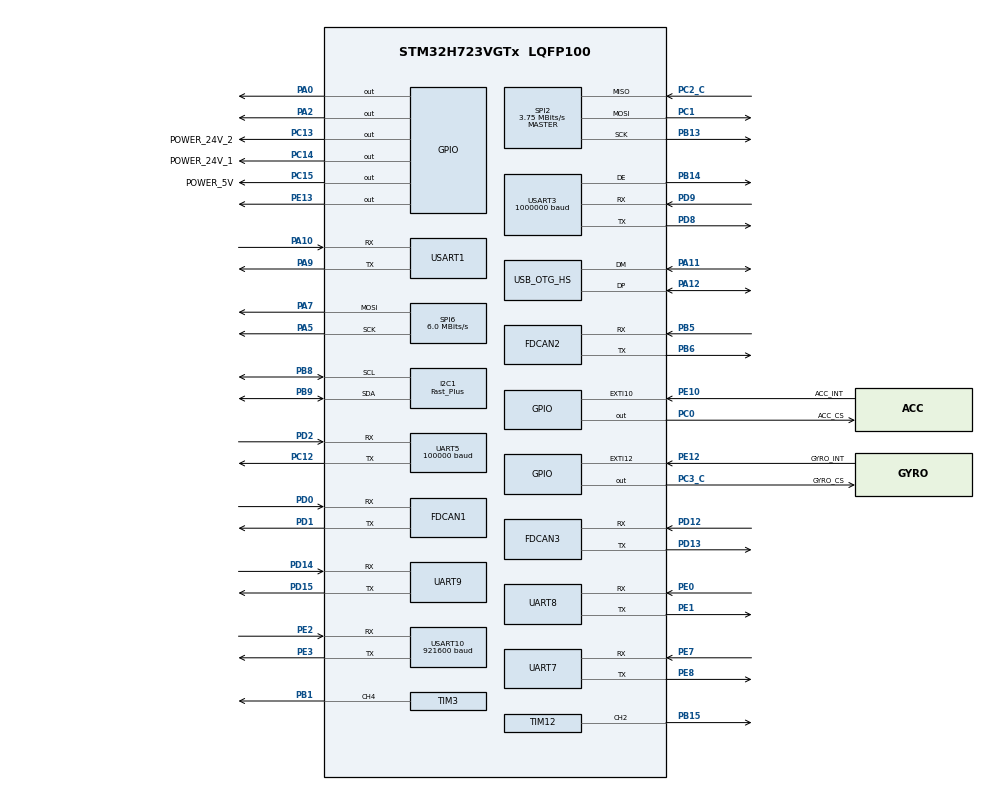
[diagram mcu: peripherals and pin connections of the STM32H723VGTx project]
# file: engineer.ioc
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ADC3.Channel-1\#ChannelRegularConversion=ADC_CHANNEL_TEMPSENSOR
ADC3.NbrOfConversionFlag=1
ADC3.OffsetNumber-1\#ChannelRegularConversion=ADC_OFFSET_NONE
ADC3.OffsetSign-1\#ChannelRegularConversion=ADC3_OFFSET_SIGN_NEGATIVE
ADC3.Rank-1\#ChannelRegularConversion=1
ADC3.SamplingTime-1\#ChannelRegularConversion=ADC3_SAMPLETIME_2CYCLES_5
Bdma.Request0=SPI6_TX
Bdma.RequestsNb=1
Bdma.SPI6_TX.0.Direction=DMA_MEMORY_TO_PERIPH
Bdma.SPI6_TX.0.EventEnable=DISABLE
Bdma.SPI6_TX.0.Instance=BDMA_Channel0
Bdma.SPI6_TX.0.MemDataAlignment=DMA_MDATAALIGN_BYTE
Bdma.SPI6_TX.0.MemInc=DMA_MINC_ENABLE
Bdma.SPI6_TX.0.Mode=DMA_NORMAL
Bdma.SPI6_TX.0.PeriphDataAlignment=DMA_PDATAALIGN_BYTE
Bdma.SPI6_TX.0.PeriphInc=DMA_PINC_DISABLE
Bdma.SPI6_TX.0.Polarity=HAL_DMAMUX_REQ_GEN_RISING
Bdma.SPI6_TX.0.Priority=DMA_PRIORITY_LOW
Bdma.SPI6_TX.0.RequestNumber=1
Bdma.SPI6_TX.0.SignalID=NONE
Bdma.SPI6_TX.0.SyncEnable=DISABLE
Bdma.SPI6_TX.0.SyncPolarity=HAL_DMAMUX_SYNC_NO_EVENT
Bdma.SPI6_TX.0.SyncRequestNumber=1
Bdma.SPI6_TX.0.SyncSignalID=NONE
CORTEX_M7.CPU_DCache=Disabled
CORTEX_M7.CPU_ICache=Disabled
CORTEX_M7.default_mode_Activation=0
Dma.Request0=UART5_RX
Dma.Request1=SPI2_RX
Dma.Request10=UART7_TX
Dma.Request11=UART9_RX
Dma.Request12=UART9_TX
Dma.Request13=UART8_RX
Dma.Request14=UART8_TX
Dma.Request2=SPI2_TX
Dma.Request3=USART10_RX
Dma.Request4=USART1_RX
Dma.Request5=USART1_TX
Dma.Request6=USART10_TX
Dma.Request7=USART3_RX
Dma.Request8=USART3_TX
Dma.Request9=UART7_RX
Dma.SPI2_RX.1.Direction=DMA_PERIPH_TO_MEMORY
Dma.SPI2_RX.1.EventEnable=DISABLE
Dma.SPI2_RX.1.FIFOMode=DMA_FIFOMODE_DISABLE
Dma.SPI2_RX.1.Instance=DMA1_Stream0
Dma.SPI2_RX.1.MemDataAlignment=DMA_MDATAALIGN_BYTE
Dma.SPI2_RX.1.MemInc=DMA_MINC_ENABLE
Dma.SPI2_RX.1.Mode=DMA_NORMAL
Dma.SPI2_RX.1.PeriphDataAlignment=DMA_PDATAALIGN_BYTE
Dma.SPI2_RX.1.PeriphInc=DMA_PINC_DISABLE
Dma.SPI2_RX.1.Polarity=HAL_DMAMUX_REQ_GEN_RISING
Dma.SPI2_RX.1.Priority=DMA_PRIORITY_VERY_HIGH
Dma.SPI2_RX.1.RequestNumber=1
Dma.SPI2_RX.1.SignalID=NONE
Dma.SPI2_RX.1.SyncEnable=DISABLE
Dma.SPI2_RX.1.SyncPolarity=HAL_DMAMUX_SYNC_NO_EVENT
Dma.SPI2_RX.1.SyncRequestNumber=1
Dma.SPI2_RX.1.SyncSignalID=NONE
Dma.SPI2_TX.2.Direction=DMA_MEMORY_TO_PERIPH
Dma.SPI2_TX.2.EventEnable=DISABLE
Dma.SPI2_TX.2.FIFOMode=DMA_FIFOMODE_DISABLE
Dma.SPI2_TX.2.Instance=DMA1_Stream1
Dma.SPI2_TX.2.MemDataAlignment=DMA_MDATAALIGN_BYTE
Dma.SPI2_TX.2.MemInc=DMA_MINC_ENABLE
Dma.SPI2_TX.2.Mode=DMA_NORMAL
Dma.SPI2_TX.2.PeriphDataAlignment=DMA_PDATAALIGN_BYTE
Dma.SPI2_TX.2.PeriphInc=DMA_PINC_DISABLE
Dma.SPI2_TX.2.Polarity=HAL_DMAMUX_REQ_GEN_RISING
Dma.SPI2_TX.2.Priority=DMA_PRIORITY_HIGH
Dma.SPI2_TX.2.RequestNumber=1
Dma.SPI2_TX.2.SignalID=NONE
Dma.SPI2_TX.2.SyncEnable=DISABLE
Dma.SPI2_TX.2.SyncPolarity=HAL_DMAMUX_SYNC_NO_EVENT
Dma.SPI2_TX.2.SyncRequestNumber=1
Dma.SPI2_TX.2.SyncSignalID=NONE
Dma.UART5_RX.0.Direction=DMA_PERIPH_TO_MEMORY
Dma.UART5_RX.0.EventEnable=DISABLE
Dma.UART5_RX.0.FIFOMode=DMA_FIFOMODE_DISABLE
Dma.UART5_RX.0.Instance=DMA1_Stream3
Dma.UART5_RX.0.MemDataAlignment=DMA_MDATAALIGN_BYTE
Dma.UART5_RX.0.MemInc=DMA_MINC_ENABLE
Dma.UART5_RX.0.Mode=DMA_NORMAL
Dma.UART5_RX.0.PeriphDataAlignment=DMA_PDATAALIGN_BYTE
Dma.UART5_RX.0.PeriphInc=DMA_PINC_DISABLE
Dma.UART5_RX.0.Polarity=HAL_DMAMUX_REQ_GEN_RISING
Dma.UART5_RX.0.Priority=DMA_PRIORITY_LOW
Dma.UART5_RX.0.RequestNumber=1
Dma.UART5_RX.0.SignalID=NONE
Dma.UART5_RX.0.SyncEnable=DISABLE
Dma.UART5_RX.0.SyncPolarity=HAL_DMAMUX_SYNC_NO_EVENT
Dma.UART5_RX.0.SyncRequestNumber=1
Dma.UART5_RX.0.SyncSignalID=NONE
Dma.UART7_RX.9.Direction=DMA_PERIPH_TO_MEMORY
Dma.UART7_RX.9.EventEnable=DISABLE
Dma.UART7_RX.9.FIFOMode=DMA_FIFOMODE_DISABLE
Dma.UART7_RX.9.Instance=DMA2_Stream1
Dma.UART7_RX.9.MemDataAlignment=DMA_MDATAALIGN_BYTE
Dma.UART7_RX.9.MemInc=DMA_MINC_ENABLE
Dma.UART7_RX.9.Mode=DMA_NORMAL
Dma.UART7_RX.9.PeriphDataAlignment=DMA_PDATAALIGN_BYTE
Dma.UART7_RX.9.PeriphInc=DMA_PINC_DISABLE
Dma.UART7_RX.9.Polarity=HAL_DMAMUX_REQ_GEN_RISING
Dma.UART7_RX.9.Priority=DMA_PRIORITY_LOW
Dma.UART7_RX.9.RequestNumber=1
Dma.UART7_RX.9.SignalID=NONE
Dma.UART7_RX.9.SyncEnable=DISABLE
Dma.UART7_RX.9.SyncPolarity=HAL_DMAMUX_SYNC_NO_EVENT
Dma.UART7_RX.9.SyncRequestNumber=1
Dma.UART7_RX.9.SyncSignalID=NONE
Dma.UART7_TX.10.Direction=DMA_MEMORY_TO_PERIPH
Dma.UART7_TX.10.EventEnable=DISABLE
Dma.UART7_TX.10.FIFOMode=DMA_FIFOMODE_DISABLE
Dma.UART7_TX.10.Instance=DMA2_Stream2
Dma.UART7_TX.10.MemDataAlignment=DMA_MDATAALIGN_BYTE
Dma.UART7_TX.10.MemInc=DMA_MINC_ENABLE
Dma.UART7_TX.10.Mode=DMA_NORMAL
Dma.UART7_TX.10.PeriphDataAlignment=DMA_PDATAALIGN_BYTE
Dma.UART7_TX.10.PeriphInc=DMA_PINC_DISABLE
Dma.UART7_TX.10.Polarity=HAL_DMAMUX_REQ_GEN_RISING
Dma.UART7_TX.10.Priority=DMA_PRIORITY_LOW
Dma.UART7_TX.10.RequestNumber=1
Dma.UART7_TX.10.SignalID=NONE
Dma.UART7_TX.10.SyncEnable=DISABLE
Dma.UART7_TX.10.SyncPolarity=HAL_DMAMUX_SYNC_NO_EVENT
Dma.UART7_TX.10.SyncRequestNumber=1
Dma.UART7_TX.10.SyncSignalID=NONE
Dma.UART8_RX.13.Direction=DMA_PERIPH_TO_MEMORY
Dma.UART8_RX.13.EventEnable=DISABLE
Dma.UART8_RX.13.FIFOMode=DMA_FIFOMODE_DISABLE
Dma.UART8_RX.13.Instance=DMA2_Stream5
Dma.UART8_RX.13.MemDataAlignment=DMA_MDATAALIGN_BYTE
Dma.UART8_RX.13.MemInc=DMA_MINC_ENABLE
Dma.UART8_RX.13.Mode=DMA_NORMAL
Dma.UART8_RX.13.PeriphDataAlignment=DMA_PDATAALIGN_BYTE
Dma.UART8_RX.13.PeriphInc=DMA_PINC_DISABLE
Dma.UART8_RX.13.Polarity=HAL_DMAMUX_REQ_GEN_RISING
Dma.UART8_RX.13.Priority=DMA_PRIORITY_LOW
Dma.UART8_RX.13.RequestNumber=1
Dma.UART8_RX.13.SignalID=NONE
Dma.UART8_RX.13.SyncEnable=DISABLE
Dma.UART8_RX.13.SyncPolarity=HAL_DMAMUX_SYNC_NO_EVENT
Dma.UART8_RX.13.SyncRequestNumber=1
Dma.UART8_RX.13.SyncSignalID=NONE
Dma.UART8_TX.14.Direction=DMA_MEMORY_TO_PERIPH
Dma.UART8_TX.14.EventEnable=DISABLE
Dma.UART8_TX.14.FIFOMode=DMA_FIFOMODE_DISABLE
Dma.UART8_TX.14.Instance=DMA2_Stream6
Dma.UART8_TX.14.MemDataAlignment=DMA_MDATAALIGN_BYTE
Dma.UART8_TX.14.MemInc=DMA_MINC_ENABLE
Dma.UART8_TX.14.Mode=DMA_NORMAL
Dma.UART8_TX.14.PeriphDataAlignment=DMA_PDATAALIGN_BYTE
Dma.UART8_TX.14.PeriphInc=DMA_PINC_DISABLE
Dma.UART8_TX.14.Polarity=HAL_DMAMUX_REQ_GEN_RISING
Dma.UART8_TX.14.Priority=DMA_PRIORITY_LOW
Dma.UART8_TX.14.RequestNumber=1
Dma.UART8_TX.14.SignalID=NONE
Dma.UART8_TX.14.SyncEnable=DISABLE
Dma.UART8_TX.14.SyncPolarity=HAL_DMAMUX_SYNC_NO_EVENT
Dma.UART8_TX.14.SyncRequestNumber=1
Dma.UART8_TX.14.SyncSignalID=NONE
Dma.UART9_RX.11.Direction=DMA_PERIPH_TO_MEMORY
Dma.UART9_RX.11.EventEnable=DISABLE
Dma.UART9_RX.11.FIFOMode=DMA_FIFOMODE_DISABLE
Dma.UART9_RX.11.Instance=DMA2_Stream3
Dma.UART9_RX.11.MemDataAlignment=DMA_MDATAALIGN_BYTE
Dma.UART9_RX.11.MemInc=DMA_MINC_ENABLE
Dma.UART9_RX.11.Mode=DMA_NORMAL
Dma.UART9_RX.11.PeriphDataAlignment=DMA_PDATAALIGN_BYTE
Dma.UART9_RX.11.PeriphInc=DMA_PINC_DISABLE
Dma.UART9_RX.11.Polarity=HAL_DMAMUX_REQ_GEN_RISING
Dma.UART9_RX.11.Priority=DMA_PRIORITY_LOW
Dma.UART9_RX.11.RequestNumber=1
Dma.UART9_RX.11.SignalID=NONE
Dma.UART9_RX.11.SyncEnable=DISABLE
Dma.UART9_RX.11.SyncPolarity=HAL_DMAMUX_SYNC_NO_EVENT
Dma.UART9_RX.11.SyncRequestNumber=1
Dma.UART9_RX.11.SyncSignalID=NONE
Dma.UART9_TX.12.Direction=DMA_MEMORY_TO_PERIPH
Dma.UART9_TX.12.EventEnable=DISABLE
Dma.UART9_TX.12.FIFOMode=DMA_FIFOMODE_DISABLE
Dma.UART9_TX.12.Instance=DMA2_Stream4
Dma.UART9_TX.12.MemDataAlignment=DMA_MDATAALIGN_BYTE
Dma.UART9_TX.12.MemInc=DMA_MINC_ENABLE
Dma.UART9_TX.12.Mode=DMA_NORMAL
Dma.UART9_TX.12.PeriphDataAlignment=DMA_PDATAALIGN_BYTE
Dma.UART9_TX.12.PeriphInc=DMA_PINC_DISABLE
Dma.UART9_TX.12.Polarity=HAL_DMAMUX_REQ_GEN_RISING
Dma.UART9_TX.12.Priority=DMA_PRIORITY_LOW
Dma.UART9_TX.12.RequestNumber=1
Dma.UART9_TX.12.SignalID=NONE
Dma.UART9_TX.12.SyncEnable=DISABLE
Dma.UART9_TX.12.SyncPolarity=HAL_DMAMUX_SYNC_NO_EVENT
Dma.UART9_TX.12.SyncRequestNumber=1
Dma.UART9_TX.12.SyncSignalID=NONE
Dma.USART10_RX.3.Direction=DMA_PERIPH_TO_MEMORY
Dma.USART10_RX.3.EventEnable=DISABLE
Dma.USART10_RX.3.FIFOMode=DMA_FIFOMODE_DISABLE
Dma.USART10_RX.3.Instance=DMA1_Stream2
Dma.USART10_RX.3.MemDataAlignment=DMA_MDATAALIGN_BYTE
Dma.USART10_RX.3.MemInc=DMA_MINC_ENABLE
Dma.USART10_RX.3.Mode=DMA_NORMAL
Dma.USART10_RX.3.PeriphDataAlignment=DMA_PDATAALIGN_BYTE
Dma.USART10_RX.3.PeriphInc=DMA_PINC_DISABLE
Dma.USART10_RX.3.Polarity=HAL_DMAMUX_REQ_GEN_RISING
Dma.USART10_RX.3.Priority=DMA_PRIORITY_MEDIUM
Dma.USART10_RX.3.RequestNumber=1
Dma.USART10_RX.3.SignalID=NONE
Dma.USART10_RX.3.SyncEnable=DISABLE
Dma.USART10_RX.3.SyncPolarity=HAL_DMAMUX_SYNC_NO_EVENT
Dma.USART10_RX.3.SyncRequestNumber=1
Dma.USART10_RX.3.SyncSignalID=NONE
Dma.USART10_TX.6.Direction=DMA_MEMORY_TO_PERIPH
Dma.USART10_TX.6.EventEnable=DISABLE
Dma.USART10_TX.6.FIFOMode=DMA_FIFOMODE_DISABLE
Dma.USART10_TX.6.Instance=DMA1_Stream6
Dma.USART10_TX.6.MemDataAlignment=DMA_MDATAALIGN_BYTE
Dma.USART10_TX.6.MemInc=DMA_MINC_ENABLE
Dma.USART10_TX.6.Mode=DMA_NORMAL
Dma.USART10_TX.6.PeriphDataAlignment=DMA_PDATAALIGN_BYTE
Dma.USART10_TX.6.PeriphInc=DMA_PINC_DISABLE
Dma.USART10_TX.6.Polarity=HAL_DMAMUX_REQ_GEN_RISING
Dma.USART10_TX.6.Priority=DMA_PRIORITY_LOW
Dma.USART10_TX.6.RequestNumber=1
Dma.USART10_TX.6.SignalID=NONE
Dma.USART10_TX.6.SyncEnable=DISABLE
Dma.USART10_TX.6.SyncPolarity=HAL_DMAMUX_SYNC_NO_EVENT
Dma.USART10_TX.6.SyncRequestNumber=1
Dma.USART10_TX.6.SyncSignalID=NONE
Dma.USART1_RX.4.Direction=DMA_PERIPH_TO_MEMORY
Dma.USART1_RX.4.EventEnable=DISABLE
Dma.USART1_RX.4.FIFOMode=DMA_FIFOMODE_DISABLE
Dma.USART1_RX.4.Instance=DMA1_Stream4
Dma.USART1_RX.4.MemDataAlignment=DMA_MDATAALIGN_BYTE
Dma.USART1_RX.4.MemInc=DMA_MINC_ENABLE
Dma.USART1_RX.4.Mode=DMA_NORMAL
Dma.USART1_RX.4.PeriphDataAlignment=DMA_PDATAALIGN_BYTE
Dma.USART1_RX.4.PeriphInc=DMA_PINC_DISABLE
Dma.USART1_RX.4.Polarity=HAL_DMAMUX_REQ_GEN_RISING
Dma.USART1_RX.4.Priority=DMA_PRIORITY_LOW
Dma.USART1_RX.4.RequestNumber=1
Dma.USART1_RX.4.SignalID=NONE
Dma.USART1_RX.4.SyncEnable=DISABLE
Dma.USART1_RX.4.SyncPolarity=HAL_DMAMUX_SYNC_NO_EVENT
Dma.USART1_RX.4.SyncRequestNumber=1
Dma.USART1_RX.4.SyncSignalID=NONE
Dma.USART1_TX.5.Direction=DMA_MEMORY_TO_PERIPH
Dma.USART1_TX.5.EventEnable=DISABLE
Dma.USART1_TX.5.FIFOMode=DMA_FIFOMODE_DISABLE
Dma.USART1_TX.5.Instance=DMA1_Stream5
Dma.USART1_TX.5.MemDataAlignment=DMA_MDATAALIGN_BYTE
Dma.USART1_TX.5.MemInc=DMA_MINC_ENABLE
Dma.USART1_TX.5.Mode=DMA_NORMAL
Dma.USART1_TX.5.PeriphDataAlignment=DMA_PDATAALIGN_BYTE
Dma.USART1_TX.5.PeriphInc=DMA_PINC_DISABLE
Dma.USART1_TX.5.Polarity=HAL_DMAMUX_REQ_GEN_RISING
Dma.USART1_TX.5.Priority=DMA_PRIORITY_LOW
Dma.USART1_TX.5.RequestNumber=1
Dma.USART1_TX.5.SignalID=NONE
Dma.USART1_TX.5.SyncEnable=DISABLE
Dma.USART1_TX.5.SyncPolarity=HAL_DMAMUX_SYNC_NO_EVENT
Dma.USART1_TX.5.SyncRequestNumber=1
Dma.USART1_TX.5.SyncSignalID=NONE
Dma.USART3_RX.7.Direction=DMA_PERIPH_TO_MEMORY
Dma.USART3_RX.7.EventEnable=DISABLE
Dma.USART3_RX.7.FIFOMode=DMA_FIFOMODE_DISABLE
Dma.USART3_RX.7.Instance=DMA1_Stream7
Dma.USART3_RX.7.MemDataAlignment=DMA_MDATAALIGN_BYTE
Dma.USART3_RX.7.MemInc=DMA_MINC_ENABLE
Dma.USART3_RX.7.Mode=DMA_NORMAL
Dma.USART3_RX.7.PeriphDataAlignment=DMA_PDATAALIGN_BYTE
Dma.USART3_RX.7.PeriphInc=DMA_PINC_DISABLE
Dma.USART3_RX.7.Polarity=HAL_DMAMUX_REQ_GEN_RISING
Dma.USART3_RX.7.Priority=DMA_PRIORITY_LOW
Dma.USART3_RX.7.RequestNumber=1
Dma.USART3_RX.7.SignalID=NONE
Dma.USART3_RX.7.SyncEnable=DISABLE
Dma.USART3_RX.7.SyncPolarity=HAL_DMAMUX_SYNC_NO_EVENT
Dma.USART3_RX.7.SyncRequestNumber=1
Dma.USART3_RX.7.SyncSignalID=NONE
Dma.USART3_TX.8.Direction=DMA_MEMORY_TO_PERIPH
Dma.USART3_TX.8.EventEnable=DISABLE
Dma.USART3_TX.8.FIFOMode=DMA_FIFOMODE_DISABLE
Dma.USART3_TX.8.Instance=DMA2_Stream0
Dma.USART3_TX.8.MemDataAlignment=DMA_MDATAALIGN_BYTE
Dma.USART3_TX.8.MemInc=DMA_MINC_ENABLE
Dma.USART3_TX.8.Mode=DMA_NORMAL
Dma.USART3_TX.8.PeriphDataAlignment=DMA_PDATAALIGN_BYTE
Dma.USART3_TX.8.PeriphInc=DMA_PINC_DISABLE
Dma.USART3_TX.8.Polarity=HAL_DMAMUX_REQ_GEN_RISING
Dma.USART3_TX.8.Priority=DMA_PRIORITY_LOW
Dma.USART3_TX.8.RequestNumber=1
Dma.USART3_TX.8.SignalID=NONE
Dma.USART3_TX.8.SyncEnable=DISABLE
Dma.USART3_TX.8.SyncPolarity=HAL_DMAMUX_SYNC_NO_EVENT
Dma.USART3_TX.8.SyncRequestNumber=1
Dma.USART3_TX.8.SyncSignalID=NONE
FDCAN1.AutoRetransmission=ENABLE
FDCAN1.CalculateBaudRateNominal=999999
FDCAN1.CalculateTimeBitNominal=1000
FDCAN1.CalculateTimeQuantumNominal=83.33333333333334
FDCAN1.DataSyncJumpWidth=2
FDCAN1.DataTimeSeg1=13
FDCAN1.DataTimeSeg2=2
FDCAN1.ExtFiltersNbr=4
FDCAN1.NominalPrescaler=10
FDCAN1.NominalSyncJumpWidth=20
FDCAN1.NominalTimeSeg1=7
FDCAN1.NominalTimeSeg2=4
FDCAN1.ProtocolException=ENABLE
FDCAN1.RxBuffersNbr=2
FDCAN1.RxFifo0ElmtsNbr=8
FDCAN1.RxFifo1ElmtsNbr=8
FDCAN1.StdFiltersNbr=4
FDCAN1.TxBuffersNbr=8
FDCAN1.TxEventsNbr=8
FDCAN1.TxFifoQueueElmtsNbr=8
FDCAN2.AutoRetransmission=ENABLE
FDCAN2.CalculateBaudRateNominal=999999
FDCAN2.CalculateTimeBitNominal=1000
FDCAN2.CalculateTimeQuantumNominal=83.33333333333334
FDCAN2.DataSyncJumpWidth=2
FDCAN2.DataTimeSeg1=13
FDCAN2.DataTimeSeg2=2
FDCAN2.ExtFiltersNbr=4
FDCAN2.MessageRAMOffset=0x406
FDCAN2.NominalPrescaler=10
FDCAN2.NominalSyncJumpWidth=20
FDCAN2.NominalTimeSeg1=7
FDCAN2.NominalTimeSeg2=4
FDCAN2.ProtocolException=ENABLE
FDCAN2.RxBuffersNbr=3
FDCAN2.RxFifo0ElmtsNbr=8
FDCAN2.RxFifo1ElmtsNbr=8
FDCAN2.StdFiltersNbr=4
FDCAN2.TxBuffersNbr=8
FDCAN2.TxEventsNbr=8
FDCAN2.TxFifoQueueElmtsNbr=8
FDCAN3.AutoRetransmission=ENABLE
FDCAN3.CalculateBaudRateNominal=999999
FDCAN3.CalculateTimeBitNominal=1000
FDCAN3.CalculateTimeQuantumNominal=83.33333333333334
FDCAN3.DataSyncJumpWidth=2
FDCAN3.DataTimeSeg1=13
FDCAN3.DataTimeSeg2=2
FDCAN3.ExtFiltersNbr=4
FDCAN3.MessageRAMOffset=0x812
FDCAN3.NominalPrescaler=10
FDCAN3.NominalSyncJumpWidth=20
FDCAN3.NominalTimeSeg1=7
FDCAN3.NominalTimeSeg2=4
FDCAN3.ProtocolException=ENABLE
FDCAN3.RxBuffersNbr=2
FDCAN3.RxFifo0ElmtsNbr=8
FDCAN3.RxFifo1ElmtsNbr=8
FDCAN3.StdFiltersNbr=4
FDCAN3.TxBuffersNbr=8
FDCAN3.TxEventsNbr=8
FDCAN3.TxFifoQueueElmtsNbr=8
FREERTOS.INCLUDE_uxTaskGetStackHighWaterMark=1
FREERTOS.INCLUDE_vTaskDelayUntil=1
FREERTOS.INCLUDE_xEventGroupSetBitFromISR=1
FREERTOS.INCLUDE_xTaskGetHandle=1
FREERTOS.INCLUDE_xTimerPendFunctionCall=1
FREERTOS.Mutexes01=CAN1Mutex,Dynamic,NULL,Depleted;CAN2Mutex,Dynamic,NULL,Available
FREERTOS.Tasks01=defaultTask,3,256,StartDefaultTask,As weak,NULL,Dynamic,NULL,NULL;LED_TASK,-1,256,OS_LedTask,As weak,NULL,Dynamic,NULL,NULL;IMU_TASK,2,512,OS_IMUTask,As weak,NULL,Dynamic,NULL,NULL;DEBUG_TASK,-1,256,OS_DebugTask,As weak,NULL,Dynamic,NULL,NULL;PC_Task,0,384,OS_PCTask,As weak,NULL,Dynamic,NULL,NULL;BUZZER_TASK,0,256,OS_BuzzerTask,As weak,NULL,Dynamic,NULL,NULL
FREERTOS.configENABLE_FPU=1
FREERTOS.configGENERATE_RUN_TIME_STATS=1
FREERTOS.configTOTAL_HEAP_SIZE=40000
FREERTOS.configUSE_RECURSIVE_MUTEXES=1
FREERTOS.configUSE_STATS_FORMATTING_FUNCTIONS=1
FREERTOS.configUSE_TIMERS=1
FREERTOS.configUSE_TRACE_FACILITY=1
I2C1.CustomTiming=Disabled
I2C1.I2C_Speed_Mode=I2C_Fast_Plus
I2C1.Speed=1000
I2C1.Timing=0x0050174F
IWDG1.Prescaler=IWDG_PRESCALER_4
IWDG1.Reload=1024
Mcu.Family=STM32H7
Mcu.Name=STM32H723VGTx
Mcu.Package=LQFP100
NVIC.BDMA_Channel0_IRQn=true\:5\:0\:false\:false\:true\:true\:false\:true\:true
NVIC.DMA1_Stream0_IRQn=true\:5\:0\:false\:false\:true\:false\:false\:true\:true
NVIC.DMA1_Stream1_IRQn=true\:5\:0\:false\:false\:true\:false\:false\:true\:true
NVIC.DMA1_Stream2_IRQn=true\:5\:0\:false\:false\:true\:true\:false\:true\:true
NVIC.DMA1_Stream3_IRQn=true\:5\:0\:false\:false\:true\:false\:false\:true\:true
NVIC.DMA1_Stream4_IRQn=true\:5\:0\:false\:false\:true\:true\:false\:true\:true
NVIC.DMA1_Stream5_IRQn=true\:5\:0\:false\:false\:true\:true\:false\:true\:true
NVIC.DMA1_Stream6_IRQn=true\:5\:0\:false\:false\:true\:true\:false\:true\:true
NVIC.DMA1_Stream7_IRQn=true\:5\:0\:false\:false\:true\:true\:false\:true\:true
NVIC.DMA2_Stream0_IRQn=true\:5\:0\:false\:false\:true\:true\:false\:true\:true
NVIC.DMA2_Stream1_IRQn=true\:5\:0\:false\:false\:true\:true\:false\:true\:true
NVIC.DMA2_Stream2_IRQn=true\:5\:0\:false\:false\:true\:true\:false\:true\:true
NVIC.DMA2_Stream3_IRQn=true\:5\:0\:false\:false\:true\:true\:false\:true\:true
NVIC.DMA2_Stream4_IRQn=true\:5\:0\:false\:false\:true\:true\:false\:true\:true
NVIC.DMA2_Stream5_IRQn=true\:5\:0\:false\:false\:true\:true\:false\:true\:true
NVIC.DMA2_Stream6_IRQn=true\:5\:0\:false\:false\:true\:true\:false\:true\:true
NVIC.EXTI15_10_IRQn=true\:5\:0\:false\:false\:true\:true\:true\:true\:true
NVIC.FDCAN1_IT0_IRQn=true\:5\:0\:false\:false\:true\:true\:true\:true\:true
NVIC.FDCAN1_IT1_IRQn=true\:5\:0\:false\:false\:true\:true\:true\:true\:true
NVIC.FDCAN2_IT0_IRQn=true\:5\:0\:false\:false\:true\:true\:true\:true\:true
NVIC.FDCAN2_IT1_IRQn=true\:5\:0\:false\:false\:true\:true\:true\:true\:true
NVIC.FDCAN3_IT0_IRQn=true\:5\:0\:false\:false\:true\:true\:true\:true\:true
NVIC.FDCAN3_IT1_IRQn=true\:5\:0\:false\:false\:true\:true\:true\:true\:true
NVIC.I2C1_ER_IRQn=true\:5\:0\:false\:false\:true\:true\:true\:true\:true
NVIC.I2C1_EV_IRQn=true\:5\:0\:false\:false\:true\:true\:true\:true\:true
NVIC.OTG_HS_IRQn=true\:5\:0\:false\:false\:true\:true\:false\:true\:true
NVIC.PriorityGroup=NVIC_PRIORITYGROUP_4
NVIC.SPI2_IRQn=true\:5\:0\:false\:false\:true\:true\:false\:true\:true
NVIC.SPI6_IRQn=true\:5\:0\:false\:false\:true\:true\:true\:true\:true
NVIC.TIM17_IRQn=true\:15\:0\:false\:false\:true\:false\:false\:true\:true
NVIC.TIM6_DAC_IRQn=true\:5\:0\:false\:false\:true\:true\:true\:true\:true
NVIC.TimeBase=TIM17_IRQn
NVIC.TimeBaseIP=TIM17
NVIC.UART5_IRQn=true\:5\:0\:false\:false\:true\:true\:true\:true\:true
NVIC.UART7_IRQn=true\:5\:0\:false\:false\:true\:true\:true\:true\:true
NVIC.UART8_IRQn=true\:5\:0\:false\:false\:true\:true\:true\:true\:true
NVIC.UART9_IRQn=true\:5\:0\:false\:false\:true\:true\:true\:true\:true
NVIC.USART10_IRQn=true\:5\:0\:false\:false\:true\:true\:true\:true\:true
NVIC.USART1_IRQn=true\:5\:0\:false\:false\:true\:true\:true\:true\:true
NVIC.USART3_IRQn=true\:5\:0\:false\:false\:true\:true\:true\:true\:true
PA0.GPIO_ModeDefaultOutputPP=GPIO_MODE_OUTPUT_OD
PA0.GPIO_PuPd=GPIO_NOPULL
PA0.GPIO_Speed=GPIO_SPEED_FREQ_VERY_HIGH
PA0.PinState=GPIO_PIN_SET
PA0.Signal=GPIO_Output
PA10.Mode=Asynchronous
PA10.Signal=USART1_RX
PA11.Mode=Device_Only_FS
PA11.Signal=USB_OTG_HS_DM
PA12.Mode=Device_Only_FS
PA12.Signal=USB_OTG_HS_DP
PA13(JTMS/SWDIO).Mode=Serial_Wire
PA13(JTMS/SWDIO).Signal=DEBUG_JTMS-SWDIO
PA14(JTCK/SWCLK).Mode=Serial_Wire
PA14(JTCK/SWCLK).Signal=DEBUG_JTCK-SWCLK
PA2.Signal=GPIO_Output
PA5.Mode=TX_Only_Simplex_Unidirect_Master
PA5.Signal=SPI6_SCK
PA7.Mode=TX_Only_Simplex_Unidirect_Master
PA7.Signal=SPI6_MOSI
PA9.Mode=Asynchronous
PA9.Signal=USART1_TX
PB1.Signal=S_TIM3_CH4
PB13.Mode=Full_Duplex_Master
PB13.Signal=SPI2_SCK
PB14.Mode=Hardware Flow Control (RS485)
PB14.Signal=USART3_DE
PB15.Signal=S_TIM12_CH2
PB5.Mode=FDCAN_Activate
PB5.Signal=FDCAN2_RX
PB6.Mode=FDCAN_Activate
PB6.Signal=FDCAN2_TX
PB8.GPIO_Pu=GPIO_NOPULL
PB8.GPIO_Speed=GPIO_SPEED_FREQ_VERY_HIGH
PB8.Mode=I2C
PB8.Signal=I2C1_SCL
PB9.GPIO_Pu=GPIO_NOPULL
PB9.GPIO_Speed=GPIO_SPEED_FREQ_VERY_HIGH
PB9.Mode=I2C
PB9.Signal=I2C1_SDA
PC0.GPIO_Label=ACC_CS
PC0.GPIO_Speed=GPIO_SPEED_FREQ_VERY_HIGH
PC0.PinState=GPIO_PIN_SET
PC0.Signal=GPIO_Output
PC1.Mode=Full_Duplex_Master
PC1.Signal=SPI2_MOSI
PC12.Mode=Asynchronous
PC12.Signal=UART5_TX
PC13.GPIO_Label=POWER_24V_2
PC13.Signal=GPIO_Output
PC14-OSC32_IN.GPIO_Label=POWER_24V_1
PC14-OSC32_IN.PinState=GPIO_PIN_RESET
PC14-OSC32_IN.Signal=GPIO_Output
PC15-OSC32_OUT.GPIO_Label=POWER_5V
PC15-OSC32_OUT.PinState=GPIO_PIN_RESET
PC15-OSC32_OUT.Signal=GPIO_Output
PC2_C.Mode=Full_Duplex_Master
PC2_C.Signal=SPI2_MISO
PC3_C.GPIO_Label=GYRO_CS
PC3_C.GPIO_Speed=GPIO_SPEED_FREQ_VERY_HIGH
PC3_C.PinState=GPIO_PIN_SET
PC3_C.Signal=GPIO_Output
PD0.Mode=FDCAN_Activate
PD0.Signal=FDCAN1_RX
PD1.Mode=FDCAN_Activate
PD1.Signal=FDCAN1_TX
PD11.Signal=OCTOSPIM_P1_IO0
PD12.Mode=FDCAN_Activate
PD12.Signal=FDCAN3_RX
PD13.Mode=FDCAN_Activate
PD13.Signal=FDCAN3_TX
PD14.Mode=Asynchronous
PD14.Signal=UART9_RX
PD15.Mode=Asynchronous
PD15.Signal=UART9_TX
PD2.Mode=Asynchronous
PD2.Signal=UART5_RX
PD8.Mode=Asynchronous
PD8.Signal=USART3_TX
PD9.Mode=Asynchronous
PD9.Signal=USART3_RX
PE0.Mode=Asynchronous
PE0.Signal=UART8_RX
PE1.Mode=Asynchronous
PE1.Signal=UART8_TX
PE10.GPIO_Label=ACC_INT
PE10.Signal=GPXTI10
PE12.GPIO_Label=GYRO_INT
PE12.Signal=GPXTI12
PE13.GPIO_PuPd=GPIO_PULLDOWN
PE13.Signal=GPIO_Output
PE2.Mode=Asynchronous
PE2.Signal=USART10_RX
PE3.Mode=Asynchronous
PE3.Signal=USART10_TX
PE7.Mode=Asynchronous
PE7.Signal=UART7_RX
PE8.Mode=Asynchronous
PE8.Signal=UART7_TX
PH0-OSC_IN.Mode=HSE-External-Oscillator
PH0-OSC_IN.Signal=RCC_OSC_IN
PH1-OSC_OUT.Mode=HSE-External-Oscillator
PH1-OSC_OUT.Signal=RCC_OSC_OUT
ProjectManager.HeapSize=0x200
ProjectManager.StackSize=0x1000
ProjectManager.TargetToolchain=CMake
RCC.ADCFreq_Value=96000000
RCC.APB1Freq_Value=120000000
RCC.APB2Freq_Value=120000000
RCC.APB3Freq_Value=120000000
RCC.APB4Freq_Value=120000000
RCC.CortexFreq_Value=480000000
RCC.D1PPRE=RCC_APB3_DIV2
RCC.D2PPRE1=RCC_APB1_DIV2
RCC.D2PPRE2=RCC_APB2_DIV2
RCC.D3PPRE=RCC_APB4_DIV2
RCC.DIVM1=2
RCC.DIVM2=2
RCC.DIVN1=40
RCC.DIVN2=16
RCC.DIVP1=1
RCC.DIVQ1=4
RCC.HCLKFreq_Value=240000000
RCC.HPRE=RCC_HCLK_DIV2
RCC.HSE_VALUE=24000000
RCC.PLL2FRACN=0
RCC.PLL3FRACN=0
RCC.PLLFRACN=0
RCC.PLLSourceVirtual=RCC_PLLSOURCE_HSE
RCC.SPI6CLockSelection=RCC_SPI6CLKSOURCE_HSE
RCC.SYSCLKFreq_VALUE=480000000
RCC.SYSCLKSource=RCC_SYSCLKSOURCE_PLLCLK
RCC.USBCLockSelection=RCC_USBCLKSOURCE_HSI48
RCC.USBFreq_Value=48000000
SH.S_TIM12_CH2.0=TIM12_CH2,PWM Generation2 CH2
SH.S_TIM3_CH4.0=TIM3_CH4,PWM Generation4 CH4
SPI2.BaudRatePrescaler=SPI_BAUDRATEPRESCALER_32
SPI2.CLKPhase=SPI_PHASE_2EDGE
SPI2.CLKPolarity=SPI_POLARITY_HIGH
SPI2.CalculateBaudRate=3.75 MBits/s
SPI2.DataSize=SPI_DATASIZE_8BIT
SPI2.Direction=SPI_DIRECTION_2LINES
SPI2.Mode=SPI_MODE_MASTER
SPI2.VirtualType=VM_MASTER
SPI6.BaudRatePrescaler=SPI_BAUDRATEPRESCALER_4
SPI6.CLKPhase=SPI_PHASE_2EDGE
SPI6.CalculateBaudRate=6.0 MBits/s
SPI6.DataSize=SPI_DATASIZE_8BIT
SPI6.Direction=SPI_DIRECTION_2LINES_TXONLY
SPI6.Mode=SPI_MODE_MASTER
SPI6.VirtualType=VM_MASTER
TIM12.Channel-PWM\ Generation2\ CH2=TIM_CHANNEL_2
TIM12.Period=2000-1
TIM12.Prescaler=24-1
TIM3.AutoReloadPreload=TIM_AUTORELOAD_PRELOAD_ENABLE
TIM3.Channel-PWM\ Generation4\ CH4=TIM_CHANNEL_4
TIM3.Period=10000-1
TIM3.Prescaler=24-1
TIM6.AutoReloadPreload=TIM_AUTORELOAD_PRELOAD_ENABLE
TIM6.Period=50-1
TIM6.Prescaler=119
UART5.BaudRate=100000
UART5.FIFOMode=FIFOMODE_DISABLE
UART5.Mode=MODE_RX
UART5.OneBitSampling=UART_ONE_BIT_SAMPLE_DISABLE
UART5.Parity=PARITY_EVEN
UART5.StopBits=UART_STOPBITS_2
UART5.SwapParam=UART_ADVFEATURE_SWAP_DISABLE
UART5.WordLength=WORDLENGTH_9B
UART8.SwapParam=UART_ADVFEATURE_SWAP_DISABLE
USART1.SwapParam=ADVFEATURE_SWAP_DISABLE
USART1.VirtualMode-Asynchronous=VM_ASYNC
USART10.BaudRate=921600
USART10.VirtualMode=VM_ASYNC
USART3.BaudRate=1000000
USART3.VirtualMode-Asynchronous=VM_ASYNC
USART3.VirtualMode-Hardware\ Flow\ Control\ (RS485)=VM_ASYNC
USB_DEVICE.CLASS_NAME_HS=CDC
USB_DEVICE.VirtualMode=Cdc
USB_DEVICE.VirtualModeHS=Cdc_HS
USB_OTG_HS.VirtualMode-Device_Only_FS=Device_Only_FS
VP_ADC3_TempSens_Input.Mode=IN-TempSens
VP_FREERTOS_VS_CMSIS_V1.Mode=CMSIS_V1
VP_IWDG1_VS_IWDG.Mode=IWDG_Activate
VP_MEMORYMAP_VS_MEMORYMAP.Mode=CurAppReg
VP_SYS_VS_tim17.Mode=TIM17
VP_TIM6_VS_ClockSourceINT.Mode=Enable_Timer
VP_USB_DEVICE_VS_USB_DEVICE_CDC_HS.Mode=CDC_HS
board=custom

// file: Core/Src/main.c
/* USER CODE BEGIN Header */
/**
  ******************************************************************************
  * @file           : main.c
  * @brief          : Main program body
  ******************************************************************************
  * @attention
  *
  * Copyright (c) 2025 STMicroelectronics.
  * All rights reserved.
  *
  * This software is licensed under terms that can be found in the LICENSE file
  * in the root directory of this software component.
  * If no LICENSE file comes with this software, it is provided AS-IS.
  *
  ******************************************************************************
  */
/* USER CODE END Header */
#include "main.h"
#include "cmsis_os.h"
#include "adc.h"
#include "bdma.h"
#include "dma.h"
#include "fdcan.h"
#include "i2c.h"
#include "iwdg.h"
#include "spi.h"
#include "tim.h"
#include "usart.h"
#include "usb_device.h"
#include "gpio.h"

void SystemClock_Config(void);
void MX_FREERTOS_Init(void);

int main(void)
{

  /* MCU Configuration--------------------------------------------------------*/

  /* Reset of all peripherals, Initializes the Flash interface and the Systick. */
  HAL_Init();

  /* Configure the system clock */
  SystemClock_Config();

  /* Initialize all configured peripherals */
  MX_GPIO_Init();
  MX_BDMA_Init();
  MX_DMA_Init();
  MX_FDCAN1_Init();
  MX_UART5_Init();
  MX_SPI6_Init();
  MX_SPI2_Init();
  MX_ADC3_Init();
  MX_TIM3_Init();
  MX_USART10_UART_Init();
  MX_FDCAN2_Init();
  MX_FDCAN3_Init();
  MX_TIM12_Init();
  MX_USART1_UART_Init();
  MX_USART3_UART_Init();
  MX_I2C1_Init();
  MX_UART7_Init();
  // MX_IWDG1_Init();
  MX_TIM6_Init();
  MX_UART9_Init();
  MX_UART8_Init();
  /* USER CODE BEGIN 2 */
	__HAL_DBGMCU_FREEZE_IWDG1();
    HAL_IWDG_Refresh(&hiwdg1);

  /* USER CODE END 2 */

  /* Call init function for freertos objects (in cmsis_os2.c) */
  MX_FREERTOS_Init();

  /* Start scheduler */
  osKernelStart();

  /* We should never get here as control is now taken by the scheduler */

  /* Infinite loop */
  while (1)
  {

  }
}

void SystemClock_Config(void)
{
  RCC_OscInitTypeDef RCC_OscInitStruct = {0};
  RCC_ClkInitTypeDef RCC_ClkInitStruct = {0};

  /** Supply configuration update enable
  */
  HAL_PWREx_ConfigSupply(PWR_LDO_SUPPLY);

  /** Configure the main internal regulator output voltage
  */
  __HAL_PWR_VOLTAGESCALING_CONFIG(PWR_REGULATOR_VOLTAGE_SCALE0);

  while(!__HAL_PWR_GET_FLAG(PWR_FLAG_VOSRDY)) {}

  /** Initializes the RCC Oscillators according to the specified parameters
  * in the RCC_OscInitTypeDef structure.
  */
  RCC_OscInitStruct.OscillatorType = RCC_OSCILLATORTYPE_HSI48|RCC_OSCILLATORTYPE_LSI
                              |RCC_OSCILLATORTYPE_HSE;
  RCC_OscInitStruct.HSEState = RCC_HSE_ON;
  RCC_OscInitStruct.LSIState = RCC_LSI_ON;
  RCC_OscInitStruct.HSI48State = RCC_HSI48_ON;
  RCC_OscInitStruct.PLL.PLLState = RCC_PLL_ON;
  RCC_OscInitStruct.PLL.PLLSource = RCC_PLLSOURCE_HSE;
  RCC_OscInitStruct.PLL.PLLM = 2;
  RCC_OscInitStruct.PLL.PLLN = 40;
  RCC_OscInitStruct.PLL.PLLP = 1;
  RCC_OscInitStruct.PLL.PLLQ = 4;
  RCC_OscInitStruct.PLL.PLLR = 2;
  RCC_OscInitStruct.PLL.PLLRGE = RCC_PLL1VCIRANGE_3;
  RCC_OscInitStruct.PLL.PLLVCOSEL = RCC_PLL1VCOWIDE;
  RCC_OscInitStruct.PLL.PLLFRACN = 0;
  if (HAL_RCC_OscConfig(&RCC_OscInitStruct) != HAL_OK)
  {
    Error_Handler();
  }

  /** Initializes the CPU, AHB and APB buses clocks
  */
  RCC_ClkInitStruct.ClockType = RCC_CLOCKTYPE_HCLK|RCC_CLOCKTYPE_SYSCLK
                              |RCC_CLOCKTYPE_PCLK1|RCC_CLOCKTYPE_PCLK2
                              |RCC_CLOCKTYPE_D3PCLK1|RCC_CLOCKTYPE_D1PCLK1;
  RCC_ClkInitStruct.SYSCLKSource = RCC_SYSCLKSOURCE_PLLCLK;
  RCC_ClkInitStruct.SYSCLKDivider = RCC_SYSCLK_DIV1;
  RCC_ClkInitStruct.AHBCLKDivider = RCC_HCLK_DIV2;
  RCC_ClkInitStruct.APB3CLKDivider = RCC_APB3_DIV2;
  RCC_ClkInitStruct.APB1CLKDivider = RCC_APB1_DIV2;
  RCC_ClkInitStruct.APB2CLKDivider = RCC_APB2_DIV2;
  RCC_ClkInitStruct.APB4CLKDivider = RCC_APB4_DIV2;

  if (HAL_RCC_ClockConfig(&RCC_ClkInitStruct, FLASH_LATENCY_3) != HAL_OK)
  {
    Error_Handler();
  }
}

void HAL_TIM_PeriodElapsedCallback(TIM_HandleTypeDef *htim)
{
  if (htim->Instance == TIM17)
  {
    HAL_IncTick();
  }
}

void Error_Handler(void)
{
  __disable_irq();
  while (1)
  {
  }
}

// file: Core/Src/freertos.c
/* USER CODE BEGIN Header */
/**
  ******************************************************************************
  * File Name          : freertos.c
  * Description        : Code for freertos applications
  ******************************************************************************
  * @attention
  *
  * Copyright (c) 2025 STMicroelectronics.
  * All rights reserved.
  *
  * This software is licensed under terms that can be found in the LICENSE file
  * in the root directory of this software component.
  * If no LICENSE file comes with this software, it is provided AS-IS.
  *
  ******************************************************************************
  */
/* USER CODE END Header */

#include "FreeRTOS.h"
#include "task.h"
#include "main.h"
#include "cmsis_os.h"

osThreadId defaultTaskHandle;
osThreadId LED_TASKHandle;
osThreadId IMU_TASKHandle;
osThreadId DEBUG_TASKHandle;
osThreadId PC_TaskHandle;
osThreadId BUZZER_TASKHandle;
osMutexId CAN1MutexHandle;
osMutexId CAN2MutexHandle;

void StartDefaultTask(void const * argument);
void OS_LedTask(void const * argument);
void OS_IMUTask(void const * argument);
void OS_DebugTask(void const * argument);
void OS_PCTask(void const * argument);
void OS_BuzzerTask(void const * argument);

extern void MX_USB_DEVICE_Init(void);
void MX_FREERTOS_Init(void); /* (MISRA C 2004 rule 8.1) */

/* GetIdleTaskMemory prototype (linked to static allocation support) */
void vApplicationGetIdleTaskMemory( StaticTask_t **ppxIdleTaskTCBBuffer, StackType_t **ppxIdleTaskStackBuffer, uint32_t *pulIdleTaskStackSize );

/* GetTimerTaskMemory prototype (linked to static allocation support) */
void vApplicationGetTimerTaskMemory( StaticTask_t **ppxTimerTaskTCBBuffer, StackType_t **ppxTimerTaskStackBuffer, uint32_t *pulTimerTaskStackSize );

/* Hook prototypes */
void configureTimerForRunTimeStats(void);
unsigned long getRunTimeCounterValue(void);

/* USER CODE BEGIN 1 */
/* Functions needed when configGENERATE_RUN_TIME_STATS is on */
__weak void configureTimerForRunTimeStats(void)
{

}

__weak unsigned long getRunTimeCounterValue(void)
{
return 0;
}
/* USER CODE END 1 */

/* USER CODE BEGIN GET_IDLE_TASK_MEMORY */
static StaticTask_t xIdleTaskTCBBuffer;
static StackType_t xIdleStack[configMINIMAL_STACK_SIZE];

void vApplicationGetIdleTaskMemory( StaticTask_t **ppxIdleTaskTCBBuffer, StackType_t **ppxIdleTaskStackBuffer, uint32_t *pulIdleTaskStackSize )
{
  *ppxIdleTaskTCBBuffer = &xIdleTaskTCBBuffer;
  *ppxIdleTaskStackBuffer = &xIdleStack[0];
  *pulIdleTaskStackSize = configMINIMAL_STACK_SIZE;
  /* place for user code */
}
/* USER CODE END GET_IDLE_TASK_MEMORY */

/* USER CODE BEGIN GET_TIMER_TASK_MEMORY */
static StaticTask_t xTimerTaskTCBBuffer;
static StackType_t xTimerStack[configTIMER_TASK_STACK_DEPTH];

void vApplicationGetTimerTaskMemory( StaticTask_t **ppxTimerTaskTCBBuffer, StackType_t **ppxTimerTaskStackBuffer, uint32_t *pulTimerTaskStackSize )
{
  *ppxTimerTaskTCBBuffer = &xTimerTaskTCBBuffer;
  *ppxTimerTaskStackBuffer = &xTimerStack[0];
  *pulTimerTaskStackSize = configTIMER_TASK_STACK_DEPTH;
  /* place for user code */
}
/* USER CODE END GET_TIMER_TASK_MEMORY */

void MX_FREERTOS_Init(void) {
  /* Create the mutex(es) */
  /* definition and creation of CAN1Mutex */
  osMutexDef(CAN1Mutex);
  CAN1MutexHandle = osMutexCreate(osMutex(CAN1Mutex));

  /* definition and creation of CAN2Mutex */
  osMutexDef(CAN2Mutex);
  CAN2MutexHandle = osMutexCreate(osMutex(CAN2Mutex));

  /* Create the thread(s) */
  /* definition and creation of defaultTask */
  osThreadDef(defaultTask, StartDefaultTask, osPriorityRealtime, 0, 256);
  defaultTaskHandle = osThreadCreate(osThread(defaultTask), NULL);

  /* definition and creation of LED_TASK */
  osThreadDef(LED_TASK, OS_LedTask, osPriorityBelowNormal, 0, 256);
  LED_TASKHandle = osThreadCreate(osThread(LED_TASK), NULL);

  /* definition and creation of IMU_TASK */
  osThreadDef(IMU_TASK, OS_IMUTask, osPriorityHigh, 0, 512);
  IMU_TASKHandle = osThreadCreate(osThread(IMU_TASK), NULL);

  /* definition and creation of DEBUG_TASK */
  osThreadDef(DEBUG_TASK, OS_DebugTask, osPriorityHigh, 0, 256);
  DEBUG_TASKHandle = osThreadCreate(osThread(DEBUG_TASK), NULL);

  /* definition and creation of PC_Task */
  osThreadDef(PC_Task, OS_PCTask, osPriorityNormal, 0, 384);
  PC_TaskHandle = osThreadCreate(osThread(PC_Task), NULL);

  /* definition and creation of BUZZER_TASK */
  osThreadDef(BUZZER_TASK, OS_BuzzerTask, osPriorityNormal, 0, 256);
  BUZZER_TASKHandle = osThreadCreate(osThread(BUZZER_TASK), NULL);

}

__weak void StartDefaultTask(void const * argument)
{
  /* init code for USB_DEVICE */
  MX_USB_DEVICE_Init();
  for(;;)
  {
    osDelay(1);
  }
}

__weak void OS_LedTask(void const * argument)
{
  for(;;)
  {
    osDelay(1);
  }
}

__weak void OS_IMUTask(void const * argument)
{
  for(;;)
  {
    osDelay(1);
  }
}

__weak void OS_DebugTask(void const * argument)
{
  for(;;)
  {
    osDelay(1);
  }
}

__weak void OS_PCTask(void const * argument)
{
  for(;;)
  {
    osDelay(1);
  }
}

__weak void OS_BuzzerTask(void const * argument)
{
  for(;;)
  {
    osDelay(1);
  }
}
